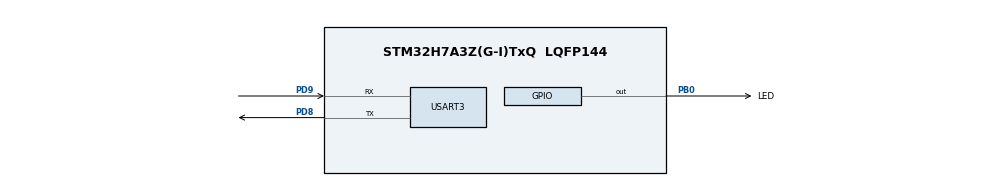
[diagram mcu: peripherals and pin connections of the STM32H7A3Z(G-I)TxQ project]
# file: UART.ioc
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CORTEX_M7.default_mode_Activation=1
Mcu.Family=STM32H7
Mcu.Name=STM32H7A3Z(G-I)TxQ
Mcu.Package=LQFP144
NVIC.PriorityGroup=NVIC_PRIORITYGROUP_4
NVIC.USART3_IRQn=true\:0\:0\:false\:false\:true\:true\:true\:true
PB0.GPIO_Label=LED
PB0.Signal=GPIO_Output
PD8.Mode=Asynchronous
PD8.Signal=USART3_TX
PD9.Mode=Asynchronous
PD9.Signal=USART3_RX
PH0-OSC_IN.Mode=HSE-External-Oscillator
PH0-OSC_IN.Signal=RCC_OSC_IN
PH1-OSC_OUT.Mode=HSE-External-Oscillator
PH1-OSC_OUT.Signal=RCC_OSC_OUT
ProjectManager.HeapSize=0x200
ProjectManager.StackSize=0x400
ProjectManager.TargetToolchain=STM32CubeIDE
RCC.ADCFreq_Value=129000000
RCC.APB1Freq_Value=64000000
RCC.APB2Freq_Value=64000000
RCC.APB3Freq_Value=64000000
RCC.APB4Freq_Value=64000000
RCC.CortexFreq_Value=64000000
RCC.DIVM1=4
RCC.DIVM3=1
RCC.DIVN1=8
RCC.DIVN3=24
RCC.DIVQ1=4
RCC.HCLKFreq_Value=64000000
RCC.HSE_VALUE=8000000
RCC.PLLFRACN=0
RCC.PWR_Regulator_Voltage_Scale=PWR_REGULATOR_VOLTAGE_SCALE0
RCC.SYSCLKFreq_VALUE=64000000
RCC.SYSCLKSource=RCC_SYSCLKSOURCE_PLLCLK
RCC.SupplySource=PWR_DIRECT_SMPS_SUPPLY
RCC.USBCLockSelection=RCC_USBCLKSOURCE_HSI48
RCC.USBFreq_Value=48000000
USART3.VirtualMode-Asynchronous=VM_ASYNC
VP_MEMORYMAP_VS_MEMORYMAP.Mode=CurAppReg
board=NUCLEO-H7A3ZI-Q

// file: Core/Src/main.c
/* USER CODE BEGIN Header */
/**
  ******************************************************************************
  * @file           : main.c
  * @brief          : Main program body
  ******************************************************************************
  * @attention
  *
  * Copyright (c) 2025 STMicroelectronics.
  * All rights reserved.
  *
  * This software is licensed under terms that can be found in the LICENSE file
  * in the root directory of this software component.
  * If no LICENSE file comes with this software, it is provided AS-IS.
  *
  ******************************************************************************
  */
/* USER CODE END Header */
#include "main.h"

/* USER CODE BEGIN Includes */

#include "pb.h"
#include "led.pb.h"
#include "pb_common.h"
#include "pb_decode.h"
#include "pb_encode.h"

/* USER CODE END Includes */

UART_HandleTypeDef huart3;
uint8_t rx_buffer[64];

/* USER CODE BEGIN PV */

// A megszakítás kezelő
void UART3_IRQHandler(void)
{
    uint8_t received_byte;

    if (__HAL_UART_GET_FLAG(&huart3, UART_FLAG_RXNE)) {
        // Egyetlen bájt beolvasása
        HAL_UART_Receive(&huart3, &received_byte, 1, HAL_MAX_DELAY);

        // Adat pufferbe helyezése
        static uint8_t index = 0;
        rx_buffer[index++] = received_byte;

        // Ha elértük a puffer méretét vagy új sor karakter érkezett, dolgozzuk fel
        if (index >= sizeof(rx_buffer) || received_byte == '\n') {
            pb_istream_t stream = pb_istream_from_buffer(rx_buffer, index);
            LedCommand led_command = LedCommand_init_zero;
            if (pb_decode(&stream, LedCommand_fields, &led_command)) {
                if (led_command.command == LedCommand_CommandType_LED_ON) {
                    HAL_GPIO_WritePin(GPIOB, GPIO_PIN_0, GPIO_PIN_SET);
                } else if (led_command.command == LedCommand_CommandType_LED_OFF) {
                    HAL_GPIO_WritePin(GPIOB, GPIO_PIN_0, GPIO_PIN_RESET);
                }
            }
            // Hibás adat esetén semmi nem történik, csak a puffer törlődik
            index = 0;  // Új adatfogadásra előkészítés
        }

        // Flag törlése
        __HAL_UART_CLEAR_FLAG(&huart3, UART_FLAG_RXNE);
    }
}

/* USER CODE END PV */

void SystemClock_Config(void);
static void MPU_Config(void);
static void MX_GPIO_Init(void);
static void MX_USART3_UART_Init(void);

int main(void)
{

  /* MPU Configuration--------------------------------------------------------*/
  MPU_Config();

  /* MCU Configuration--------------------------------------------------------*/

  /* Reset of all peripherals, Initializes the Flash interface and the Systick. */
  HAL_Init();

  /* Configure the system clock */
  SystemClock_Config();

  /* Initialize all configured peripherals */
  MX_GPIO_Init();
  MX_USART3_UART_Init();
  /* USER CODE BEGIN 2 */

  HAL_UART_Receive_IT(&huart3, rx_buffer, sizeof(rx_buffer));

  /* USER CODE END 2 */

  /* Infinite loop */
  while (1)
  {

  }
}

void SystemClock_Config(void)
{
  RCC_OscInitTypeDef RCC_OscInitStruct = {0};
  RCC_ClkInitTypeDef RCC_ClkInitStruct = {0};

  /*AXI clock gating */
  RCC->CKGAENR = 0xFFFFFFFF;

  /** Supply configuration update enable
  */
  HAL_PWREx_ConfigSupply(PWR_DIRECT_SMPS_SUPPLY);

  /** Configure the main internal regulator output voltage
  */
  __HAL_PWR_VOLTAGESCALING_CONFIG(PWR_REGULATOR_VOLTAGE_SCALE0);

  while(!__HAL_PWR_GET_FLAG(PWR_FLAG_VOSRDY)) {}

  /** Initializes the RCC Oscillators according to the specified parameters
  * in the RCC_OscInitTypeDef structure.
  */
  RCC_OscInitStruct.OscillatorType = RCC_OSCILLATORTYPE_HSI;
  RCC_OscInitStruct.HSIState = RCC_HSI_DIV1;
  RCC_OscInitStruct.HSICalibrationValue = 64;
  RCC_OscInitStruct.PLL.PLLState = RCC_PLL_ON;
  RCC_OscInitStruct.PLL.PLLSource = RCC_PLLSOURCE_HSI;
  RCC_OscInitStruct.PLL.PLLM = 4;
  RCC_OscInitStruct.PLL.PLLN = 8;
  RCC_OscInitStruct.PLL.PLLP = 2;
  RCC_OscInitStruct.PLL.PLLQ = 4;
  RCC_OscInitStruct.PLL.PLLR = 2;
  RCC_OscInitStruct.PLL.PLLRGE = RCC_PLL1VCIRANGE_3;
  RCC_OscInitStruct.PLL.PLLVCOSEL = RCC_PLL1VCOWIDE;
  RCC_OscInitStruct.PLL.PLLFRACN = 0;
  if (HAL_RCC_OscConfig(&RCC_OscInitStruct) != HAL_OK)
  {
    Error_Handler();
  }

  /** Initializes the CPU, AHB and APB buses clocks
  */
  RCC_ClkInitStruct.ClockType = RCC_CLOCKTYPE_HCLK|RCC_CLOCKTYPE_SYSCLK
                              |RCC_CLOCKTYPE_PCLK1|RCC_CLOCKTYPE_PCLK2
                              |RCC_CLOCKTYPE_D3PCLK1|RCC_CLOCKTYPE_D1PCLK1;
  RCC_ClkInitStruct.SYSCLKSource = RCC_SYSCLKSOURCE_PLLCLK;
  RCC_ClkInitStruct.SYSCLKDivider = RCC_SYSCLK_DIV1;
  RCC_ClkInitStruct.AHBCLKDivider = RCC_HCLK_DIV1;
  RCC_ClkInitStruct.APB3CLKDivider = RCC_APB3_DIV1;
  RCC_ClkInitStruct.APB1CLKDivider = RCC_APB1_DIV1;
  RCC_ClkInitStruct.APB2CLKDivider = RCC_APB2_DIV1;
  RCC_ClkInitStruct.APB4CLKDivider = RCC_APB4_DIV1;

  if (HAL_RCC_ClockConfig(&RCC_ClkInitStruct, FLASH_LATENCY_1) != HAL_OK)
  {
    Error_Handler();
  }
}

static void MX_USART3_UART_Init(void)
{

  huart3.Instance = USART3;
  huart3.Init.BaudRate = 115200;
  huart3.Init.WordLength = UART_WORDLENGTH_8B;
  huart3.Init.StopBits = UART_STOPBITS_1;
  huart3.Init.Parity = UART_PARITY_NONE;
  huart3.Init.Mode = UART_MODE_TX_RX;
  huart3.Init.HwFlowCtl = UART_HWCONTROL_NONE;
  huart3.Init.OverSampling = UART_OVERSAMPLING_16;
  huart3.Init.OneBitSampling = UART_ONE_BIT_SAMPLE_DISABLE;
  huart3.Init.ClockPrescaler = UART_PRESCALER_DIV1;
  huart3.AdvancedInit.AdvFeatureInit = UART_ADVFEATURE_NO_INIT;
  if (HAL_UART_Init(&huart3) != HAL_OK)
  {
    Error_Handler();
  }
  if (HAL_UARTEx_SetTxFifoThreshold(&huart3, UART_TXFIFO_THRESHOLD_1_8) != HAL_OK)
  {
    Error_Handler();
  }
  if (HAL_UARTEx_SetRxFifoThreshold(&huart3, UART_RXFIFO_THRESHOLD_1_8) != HAL_OK)
  {
    Error_Handler();
  }
  if (HAL_UARTEx_DisableFifoMode(&huart3) != HAL_OK)
  {
    Error_Handler();
  }

}

static void MX_GPIO_Init(void)
{
  GPIO_InitTypeDef GPIO_InitStruct = {0};

  /* GPIO Ports Clock Enable */
  __HAL_RCC_GPIOH_CLK_ENABLE();
  __HAL_RCC_GPIOB_CLK_ENABLE();
  __HAL_RCC_GPIOD_CLK_ENABLE();

  /*Configure GPIO pin Output Level */
  HAL_GPIO_WritePin(LED_GPIO_Port, LED_Pin, GPIO_PIN_RESET);

  /*Configure GPIO pin : LED_Pin */
  GPIO_InitStruct.Pin = LED_Pin;
  GPIO_InitStruct.Mode = GPIO_MODE_OUTPUT_PP;
  GPIO_InitStruct.Pull = GPIO_NOPULL;
  GPIO_InitStruct.Speed = GPIO_SPEED_FREQ_LOW;
  HAL_GPIO_Init(LED_GPIO_Port, &GPIO_InitStruct);

}

 /* MPU Configuration */

void MPU_Config(void)
{
  MPU_Region_InitTypeDef MPU_InitStruct = {0};

  /* Disables the MPU */
  HAL_MPU_Disable();

  /** Initializes and configures the Region and the memory to be protected
  */
  MPU_InitStruct.Enable = MPU_REGION_ENABLE;
  MPU_InitStruct.Number = MPU_REGION_NUMBER0;
  MPU_InitStruct.BaseAddress = 0x0;
  MPU_InitStruct.Size = MPU_REGION_SIZE_4GB;
  MPU_InitStruct.SubRegionDisable = 0x87;
  MPU_InitStruct.TypeExtField = MPU_TEX_LEVEL0;
  MPU_InitStruct.AccessPermission = MPU_REGION_NO_ACCESS;
  MPU_InitStruct.DisableExec = MPU_INSTRUCTION_ACCESS_DISABLE;
  MPU_InitStruct.IsShareable = MPU_ACCESS_SHAREABLE;
  MPU_InitStruct.IsCacheable = MPU_ACCESS_NOT_CACHEABLE;
  MPU_InitStruct.IsBufferable = MPU_ACCESS_NOT_BUFFERABLE;

  HAL_MPU_ConfigRegion(&MPU_InitStruct);
  /* Enables the MPU */
  HAL_MPU_Enable(MPU_PRIVILEGED_DEFAULT);

}

void Error_Handler(void)
{
  __disable_irq();
  while (1)
  {
  }
}
